# ipro7 register map
Vendor: intelpro; Series: BTBLE
CPU: ipro7, little endian
Registers are 32-bit, read-write, reset 0x0 unless marked. A register's access mark holds for its fields unless they carry their own. Offsets are from the block's base; [hi:lo] are bit positions.

## MMM
Base 0x30040000
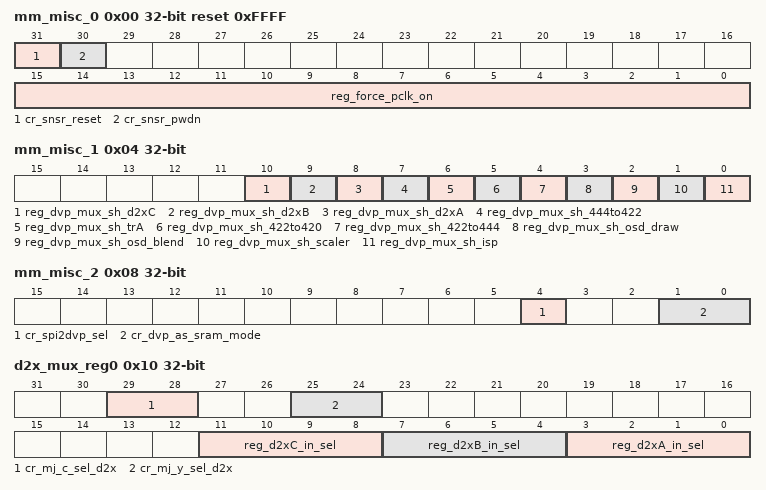
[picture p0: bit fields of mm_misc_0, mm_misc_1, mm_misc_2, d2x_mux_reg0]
0x00 mm_misc_0 reset 0xFFFF
  [31] cr_snsr_reset
  [30] cr_snsr_pwdn
  [15:0] reg_force_pclk_on — Force pclk free run
0x04 mm_misc_1
  [10] reg_dvp_mux_sh_d2xC wo — force dvp mux shadow
  [9] reg_dvp_mux_sh_d2xB wo — force dvp mux shadow
  [8] reg_dvp_mux_sh_d2xA wo — force dvp mux shadow
  [7] reg_dvp_mux_sh_444to422 wo — force dvp mux shadow
  [6] reg_dvp_mux_sh_trA wo — force dvp mux shadow
  [5] reg_dvp_mux_sh_422to420 wo — force dvp mux shadow
  [4] reg_dvp_mux_sh_422to444 wo — force dvp mux shadow
  [3] reg_dvp_mux_sh_osd_draw wo — force dvp mux shadow
  [2] reg_dvp_mux_sh_osd_blend wo — force dvp mux shadow
  [1] reg_dvp_mux_sh_scaler wo — force dvp mux shadow
  [0] reg_dvp_mux_sh_isp wo — force dvp mux shadow
0x08 mm_misc_2
  [4] cr_spi2dvp_sel — SPI2DVP selection 1'b0 - SPI 1'b1 - SPI_2
  [1:0] cr_dvp_as_sram_mode — DVP AS SRAM share mode 2'd0 - DVP_AS 2'd1 - SPI2DVP 2'd2 - DVP_TSRC
0x10 d2x_mux_reg0
  [29:28] cr_mj_c_sel_d2x — JENC Y/C hw mode, dvp2axi selection 2'd0 - d2xA 2'd1 - d2xB others - d2xC
  [25:24] cr_mj_y_sel_d2x
  [11:8] reg_d2xC_in_sel — DVP2AXI Mux selection [0] spi2dvp [1] dvp_as [2] isp_out [3] ScalerHydre_f0 [4] ScalerHydre_f1 [5] osd.blend [6] osd.draw [7] yuv444to422 [8] blai [9] dvp_tsrc [10] yuv422to444 [11] yuv2rgb [12] yuv422to420 [13] isp_debug_ink0 [14] isp_debug_ink1
  [7:4] reg_d2xB_in_sel
  [3:0] reg_d2xA_in_sel
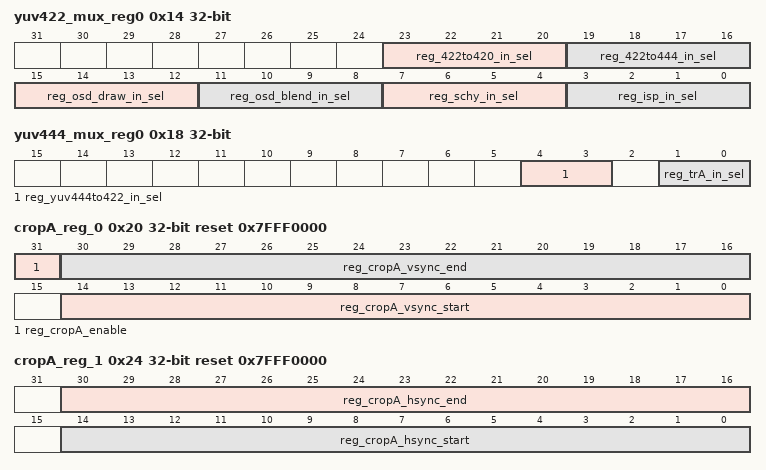
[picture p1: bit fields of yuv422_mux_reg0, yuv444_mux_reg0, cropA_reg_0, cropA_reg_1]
0x14 yuv422_mux_reg0
  [23:20] reg_422to420_in_sel — YUV422 Mux selection [0] spi2dvp [1] dvp_as [2] isp_out [3] ScalerHydre_f0 [4] ScalerHydre_f1 [5] osd.blend [6] osd.draw [7] yuv444to422 [8] blai [9] dvp_tsrc
  [19:16] reg_422to444_in_sel
  [15:12] reg_osd_draw_in_sel
  [11:8] reg_osd_blend_in_sel
  [7:4] reg_schy_in_sel
  [3:0] reg_isp_in_sel
0x18 yuv444_mux_reg0
  [4:3] reg_yuv444to422_in_sel — YUV444/RGB888 Mux selection [0] yuv422to444 [1] yuv2rgb [2] blai [3] dvp_tsrc
  [1:0] reg_trA_in_sel
0x20 cropA_reg_0 reset 0x7FFF0000
  [31] reg_cropA_enable — Enable signal
  [30:16] reg_cropA_vsync_end — Crop vsync valid end
  [14:0] reg_cropA_vsync_start — Crop vsync valid start
0x24 cropA_reg_1 reset 0x7FFF0000
  [30:16] reg_cropA_hsync_end — Crop hsync valid end
  [14:0] reg_cropA_hsync_start — Crop hsync valid start
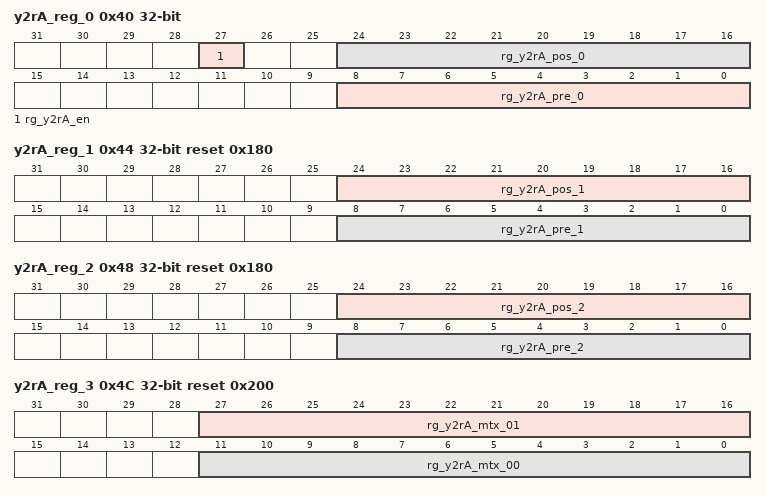
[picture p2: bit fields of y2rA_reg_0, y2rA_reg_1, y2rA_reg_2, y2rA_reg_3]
0x40 y2rA_reg_0
  [27] rg_y2rA_en — YUV2RGB_A Enable
  [24:16] rg_y2rA_pos_0 — YUV2RGB "post_offset_0" parameter
  [8:0] rg_y2rA_pre_0 — YUV2RGB "pre_offset_0" parameter
0x44 y2rA_reg_1 reset 0x180
  [24:16] rg_y2rA_pos_1 — YUV2RGB "post_offset_1" parameter
  [8:0] rg_y2rA_pre_1 — YUV2RGB "pre_offset_1" parameter
0x48 y2rA_reg_2 reset 0x180
  [24:16] rg_y2rA_pos_2 — YUV2RGB "post_offset_2" parameter
  [8:0] rg_y2rA_pre_2 — YUV2RGB "pre_offset_2" parameter
0x4C y2rA_reg_3 reset 0x200
  [27:16] rg_y2rA_mtx_01 — YUV2RGB "matrix_01" parameter
  [11:0] rg_y2rA_mtx_00 — YUV2RGB "matrix_00" parameter
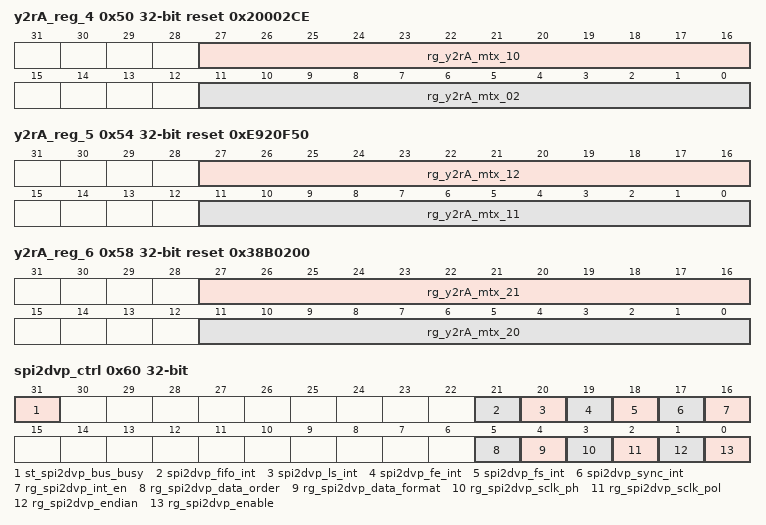
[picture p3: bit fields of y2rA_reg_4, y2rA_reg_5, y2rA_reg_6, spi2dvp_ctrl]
0x50 y2rA_reg_4 reset 0x20002CE
  [27:16] rg_y2rA_mtx_10 — YUV2RGB "matrix_10" parameter
  [11:0] rg_y2rA_mtx_02 — YUV2RGB "matrix_02" parameter
0x54 y2rA_reg_5 reset 0xE920F50
  [27:16] rg_y2rA_mtx_12 — YUV2RGB "matrix_12" parameter
  [11:0] rg_y2rA_mtx_11 — YUV2RGB "matrix_11" parameter
0x58 y2rA_reg_6 reset 0x38B0200
  [27:16] rg_y2rA_mtx_21 — YUV2RGB "matrix_21" parameter
  [11:0] rg_y2rA_mtx_20 — YUV2RGB "matrix_20" parameter
0x5C y2rA_reg_7
  [11:0] rg_y2rA_mtx_22 — YUV2RGB "matrix_22" parameter
0x60 spi2dvp_ctrl (reset mask 0x7FC1FFFF)
  [31] st_spi2dvp_bus_busy ro — SPI interface busy indicator
  [21] spi2dvp_fifo_int ro — FIFO overrun interrupt, considered ERROR and can be cleared by deasserting rg_spi2dvp_int_en
  [20] spi2dvp_ls_int ro — Interrupt asserted when Line Start packet is received, can be cleared by deasserting rg_spi2dvp_int_en
  [19] spi2dvp_fe_int ro — Interrupt asserted when Frame End packet is received, can be cleared by deasserting rg_spi2dvp_int_en
  [18] spi2dvp_fs_int ro — Interrupt asserted when Frame Start packet is received, can be cleared by deasserting rg_spi2dvp_int_en
  [17] spi2dvp_sync_int ro — Interrupt asserted when SYNC code is received, can be cleared by deasserting rg_spi2dvp_int_en
  [16] rg_spi2dvp_int_en — SPI2DVP interrupt enable
  [5] rg_spi2dvp_data_order — SPI2DVP data order (don't-care if data format is YUV400) 0: U/V first 1: Y first
  [4] rg_spi2dvp_data_format — SPI2DVP data format 0: YUV422 1: YUV400 (Y only)
  [3] rg_spi2dvp_sclk_ph — SPI interface SCLK phase
  [2] rg_spi2dvp_sclk_pol — SPI interface SCLK polarity
  [1] rg_spi2dvp_endian — SPI interface data endian 0: LSB first 1: MSB first
  [0] rg_spi2dvp_enable — SPI2DVP function enable
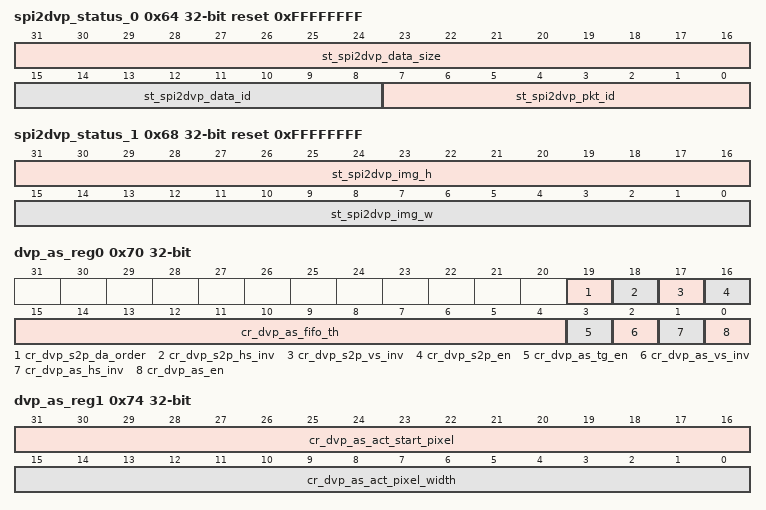
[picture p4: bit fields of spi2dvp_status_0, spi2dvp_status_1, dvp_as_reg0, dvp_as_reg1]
0x64 spi2dvp_status_0 reset 0xFFFFFFFF (reset mask 0x0)
  [31:16] st_spi2dvp_data_size ro — Data size received
  [15:8] st_spi2dvp_data_id ro — Data ID received
  [7:0] st_spi2dvp_pkt_id ro — Packet ID received
0x68 spi2dvp_status_1 reset 0xFFFFFFFF (reset mask 0x0)
  [31:16] st_spi2dvp_img_h ro — Image height received
  [15:0] st_spi2dvp_img_w ro — Image width received
0x70 dvp_as_reg0
  [19] cr_dvp_s2p_da_order — Input data order 1'b0: The first data is lower-byte 1'b1: The first data is higher-byte
  [18] cr_dvp_s2p_hs_inv — Input H-Sync inverse signal 1'b0: Input is already active-high (no inverse) 1'b1: Input is active-low (inversed)
  [17] cr_dvp_s2p_vs_inv — Input V-Sync inverse signal 1'b0: Input is already active-high (no inverse) 1'b1: Input is active-low (inversed)
  [16] cr_dvp_s2p_en — Input data format 1'b1: YUV422 1'b0: YUV400 (Y-only)
  [15:4] cr_dvp_as_fifo_th — FIFO threshold for each DVP line to start to output
  [3] cr_dvp_as_tg_en — Auto generate hsync @ H-Blanking
  [2] cr_dvp_as_vs_inv — Input V-Sync inverse signal 1'b0: Input is already active-high (no inverse) 1'b1: Input is active-low (inversed)
  [1] cr_dvp_as_hs_inv — Input H-Sync inverse signal 1'b0: Input is already active-high (no inverse) 1'b1: Input is active-low (inversed)
  [0] cr_dvp_as_en — Enable signal
0x74 dvp_as_reg1
  [31:16] cr_dvp_as_act_start_pixel — Auto generate hsync @ H-Blanking
  [15:0] cr_dvp_as_act_pixel_width — Auto generate hsync @ H-Blanking
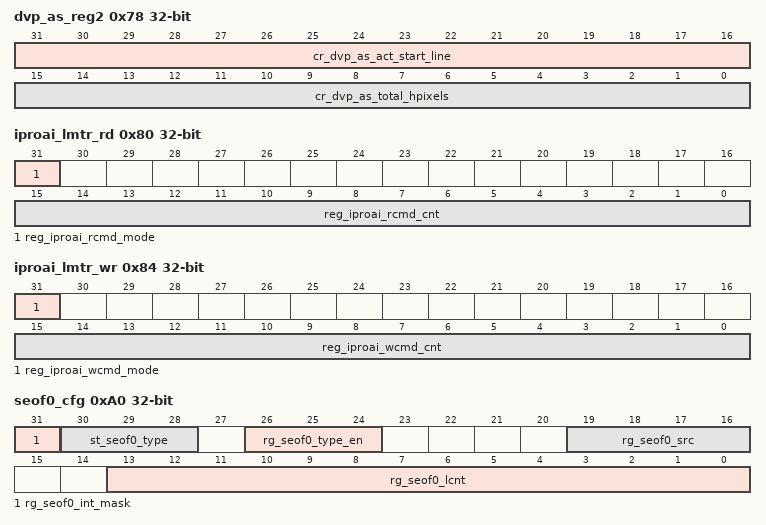
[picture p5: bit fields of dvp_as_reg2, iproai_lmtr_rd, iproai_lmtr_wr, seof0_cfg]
0x78 dvp_as_reg2
  [31:16] cr_dvp_as_act_start_line — Auto generate hsync @ H-Blanking
  [15:0] cr_dvp_as_total_hpixels — Auto generate hsync @ H-Blanking
0x7C dvp_as_reg3
  [15:0] cr_dvp_as_act_line_height — Auto generate hsync @ H-Blanking
0x80 iproai_lmtr_rd
  [31] reg_iproai_rcmd_mode — IPROAI AXI limiter command mode 1'b0 - Bypass mode 1'b1 - Fix latency mode
  [15:0] reg_iproai_rcmd_cnt — IPROAI AXI limiter command latency Count (Only work when reg_iproai_rcmd_mode=1)
0x84 iproai_lmtr_wr
  [31] reg_iproai_wcmd_mode — IPROAI AXI limiter command mode 1'b0 - Bypass mode 1'b1 - Fix latency mode
  [15:0] reg_iproai_wcmd_cnt — IPROAI AXI limiter command latency Count (Only work when reg_iproai_wcmd_mode=1)
0xA0 seof0_cfg (reset mask 0x8FFFFFFF)
  [31] rg_seof0_int_mask — S/E-oF interrupt mask
  [30:28] st_seof0_type ro — S/E-oF interrupt type status [0] Frame start (vsync rising) [1] Frame done (vsync falling) [2] : Specific line on frame valid
  [26:24] rg_seof0_type_en — S/E-oF interrupt type enable [0] Frame start (vsync rising) [1] Frame done (vsync falling) [2] : Specific line on frame valid
  [19:16] rg_seof0_src — S/E-oF interrupt source.(Refer to dvp_mux sheet dvp2axi part)
  [13:0] rg_seof0_lcnt — Specifi line count seof interrupt
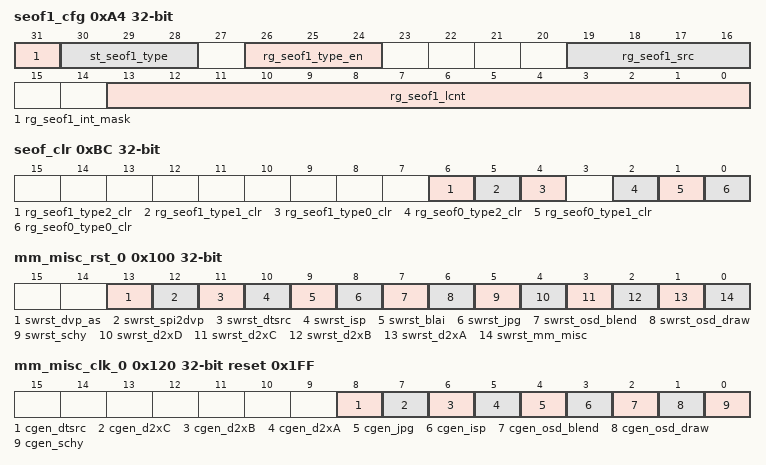
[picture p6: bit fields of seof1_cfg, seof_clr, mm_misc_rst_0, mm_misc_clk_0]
0xA4 seof1_cfg (reset mask 0x8FFFFFFF)
  [31] rg_seof1_int_mask — S/E-oF interrupt mask
  [30:28] st_seof1_type ro — S/E-oF interrupt type status [0] Frame start (vsync rising) [1] Frame done (vsync falling) [2] : Specific line on frame valid
  [26:24] rg_seof1_type_en — S/E-oF interrupt type enable [0] Frame start (vsync rising) [1] Frame done (vsync falling) [2] : Specific line on frame valid
  [19:16] rg_seof1_src — S/E-oF interrupt source.(Refer to dvp_mux sheet dvp2axi part)
  [13:0] rg_seof1_lcnt — Specifi line count seof interrupt
0xBC seof_clr
  [6] rg_seof1_type2_clr wo — SE-oF interrupt clear - Specific line on frame valid
  [5] rg_seof1_type1_clr wo — SE-oF interrupt clear - Frame done (vsync falling)
  [4] rg_seof1_type0_clr wo — SE-oF interrupt clear - Frame start (vsync rising)
  [2] rg_seof0_type2_clr wo — SE-oF interrupt clear - Specific line on frame valid
  [1] rg_seof0_type1_clr wo — SE-oF interrupt clear - Frame done (vsync falling)
  [0] rg_seof0_type0_clr wo — SE-oF interrupt clear - Frame start (vsync rising)
0x100 mm_misc_rst_0
  [13] swrst_dvp_as, [12] swrst_spi2dvp, [11] swrst_dtsrc, [10] swrst_isp, [9] swrst_blai, [8] swrst_jpg, [7] swrst_osd_blend, [6] swrst_osd_draw, [5] swrst_schy, [4] swrst_d2xD, [3] swrst_d2xC, [2] swrst_d2xB, [1] swrst_d2xA, [0] swrst_mm_misc
0x120 mm_misc_clk_0 reset 0x1FF
  [8] cgen_dtsrc, [7] cgen_d2xC, [6] cgen_d2xB, [5] cgen_d2xA, [4] cgen_jpg, [3] cgen_isp, [2] cgen_osd_blend, [1] cgen_osd_draw, [0] cgen_schy
